# MCXC444 register map
Vendor: NXP Semiconductors; Series: MCX; File version: 1.6
CPU: CM0PLUS r0p0, little endian, no MPU, no FPU, VTOR, 2 interrupt priority bits
Registers are 32-bit, read-write, reset 0x0 unless marked. A register's access mark holds for its fields unless they carry their own. Offsets are from the block's base; [hi:lo] are bit positions; {n}, {i} and the like mark numbered series.

## FTFA_FlashConfig — Flash configuration field
Base 0x00000400; register names take the prefix NV_
0x00 BACKKEY3 8-bit ro reset 0xFF — Backdoor Comparison Key 3.
  [7:0] KEY — Backdoor Comparison Key.
0x01 BACKKEY2 8-bit ro reset 0xFF — Backdoor Comparison Key 2.
  [7:0] KEY — Backdoor Comparison Key.
0x02 BACKKEY1 8-bit ro reset 0xFF — Backdoor Comparison Key 1.
  [7:0] KEY — Backdoor Comparison Key.
0x03 BACKKEY0 8-bit ro reset 0xFF — Backdoor Comparison Key 0.
  [7:0] KEY — Backdoor Comparison Key.
0x04 BACKKEY7 8-bit ro reset 0xFF — Backdoor Comparison Key 7.
  [7:0] KEY — Backdoor Comparison Key.
0x05 BACKKEY6 8-bit ro reset 0xFF — Backdoor Comparison Key 6.
  [7:0] KEY — Backdoor Comparison Key.
0x06 BACKKEY5 8-bit ro reset 0xFF — Backdoor Comparison Key 5.
  [7:0] KEY — Backdoor Comparison Key.
0x07 BACKKEY4 8-bit ro reset 0xFF — Backdoor Comparison Key 4.
  [7:0] KEY — Backdoor Comparison Key.
0x08 FPROT3 8-bit ro reset 0xFF — Non-volatile P-Flash Protection 1 - Low Register
  [7:0] PROT — P-Flash Region Protect
0x09 FPROT2 8-bit ro reset 0xFF — Non-volatile P-Flash Protection 1 - High Register
  [7:0] PROT — P-Flash Region Protect
0x0A FPROT1 8-bit ro reset 0xFF — Non-volatile P-Flash Protection 0 - Low Register
  [7:0] PROT — P-Flash Region Protect
0x0B FPROT0 8-bit ro reset 0xFF — Non-volatile P-Flash Protection 0 - High Register
  [7:0] PROT — P-Flash Region Protect
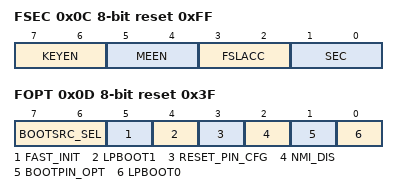
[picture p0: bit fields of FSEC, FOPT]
0x0C FSEC 8-bit ro reset 0xFF — Non-volatile Flash Security Register
  [7:6] KEYEN — Backdoor Key Security Enable
    2=b10 (Backdoor key access enabled); 3=b11 (Backdoor key access disabled)
  [5:4] MEEN
    2=b10 (Mass erase is disabled); 3=b11 (Mass erase is enabled)
  [3:2] FSLACC — Freescale Failure Analysis Access Code
    2=b10 (Freescale factory access denied); 3=b11 (Freescale factory access granted)
  [1:0] SEC — Flash Security
    2=b10 (MCU security status is unsecure); 3=b11 (MCU security status is secure)
0x0D FOPT 8-bit ro reset 0x3F — Non-volatile Flash Option Register
  [7:6] BOOTSRC_SEL — Boot source selection
    0=b00 (Boot from Flash); 2=b10 (Boot from ROM); 3=b11 (Boot from ROM)
  [5] FAST_INIT
    0=b0 (Slower initialization); 1=b1 (Fast Initialization)
  [4] LPBOOT1
    0=b0 (Core and system clock divider (OUTDIV1) is 0x7 (divide by 8) when LPBOOT0=0 or 0x3 (divide by 4) when LPBOOT0=1.); 1=b1 (Core and system clock divider (OUTDIV1) is 0x1 (divide by 2) when LPBOOT0=0 or 0x0 (divide by 1) when LPBOOT0=1.)
  [3] RESET_PIN_CFG
    0=b0 (RESET pin is disabled following a POR and cannot be enabled as reset function); 1=b1 (RESET_b pin is dedicated)
  [2] NMI_DIS
    0=b0 (NMI interrupts are always blocked); 1=b1 (NMI_b pin/interrupts reset default to enabled)
  [1] BOOTPIN_OPT
    0=b0 (Force Boot from ROM if BOOTCFG0 asserted, where BOOTCFG0 is the boot config function which is muxed with NMI pin); 1=b1 (Boot source configured by FOPT (BOOTSRC_SEL) bits)
  [0] LPBOOT0
    0=b0 (Core and system clock divider (OUTDIV1) is 0x7 (divide by 8) when LPBOOT1=0 or 0x1 (divide by 2) when LPBOOT1=1.); 1=b1 (Core and system clock divider (OUTDIV1) is 0x3 (divide by 4) when LPBOOT1=0 or 0x0 (divide by 1) when LPBOOT1=1.)

## FTFA — Flash Memory Interface
Base 0x40020000; register names take the prefix FTFA_
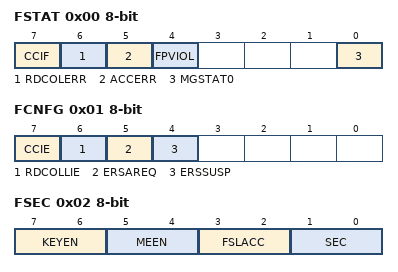
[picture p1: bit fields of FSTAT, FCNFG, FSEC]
0x00 FSTAT 8-bit — Flash Status Register
  [7] CCIF — Command Complete Interrupt Flag
    0=b0 (Flash command in progress); 1=b1 (Flash command has completed)
  [6] RDCOLERR — Flash Read Collision Error Flag
    0=b0 (No collision error detected); 1=b1 (Collision error detected)
  [5] ACCERR — Flash Access Error Flag
    0=b0 (No access error detected); 1=b1 (Access error detected)
  [4] FPVIOL — Flash Protection Violation Flag
    0=b0 (No protection violation detected); 1=b1 (Protection violation detected)
  [0] MGSTAT0 ro — Memory Controller Command Completion Status Flag
0x01 FCNFG 8-bit — Flash Configuration Register
  [7] CCIE — Command Complete Interrupt Enable
    0=b0 (Command complete interrupt disabled); 1=b1 (Command complete interrupt enabled. An interrupt request is generated whenever the FSTAT[CCIF] flag is set.)
  [6] RDCOLLIE — Read Collision Error Interrupt Enable
    0=b0 (Read collision error interrupt disabled); 1=b1 (Read collision error interrupt enabled. An interrupt request is generated whenever a flash memory read collision error is detected (see the description of FSTAT[RDCOLERR]).)
  [5] ERSAREQ ro — Erase All Request
    0=b0 (No request or request complete); 1=b1 (Request to: run the Erase All Blocks command, verify the erased state, program the security byte in the Flash Configuration Field to the unsecure state, and release MCU security by setting the FSEC[SEC] field to the unsecure state.)
  [4] ERSSUSP — Erase Suspend
    0=b0 (No suspend requested); 1=b1 (Suspend the current Erase Flash Sector command execution.)
0x02 FSEC 8-bit ro reset not defined — Flash Security Register
  [7:6] KEYEN — Backdoor Key Security Enable
    0=b00 (Backdoor key access disabled); 1=b01 (Backdoor key access disabled (preferred KEYEN state to disable backdoor key access)); 2=b10 (Backdoor key access enabled); 3=b11 (Backdoor key access disabled)
  [5:4] MEEN — Mass Erase Enable Bits
    0=b00 (Mass erase is enabled); 1=b01 (Mass erase is enabled); 2=b10 (Mass erase is disabled); 3=b11 (Mass erase is enabled)
  [3:2] FSLACC — Freescale Failure Analysis Access Code
    0=b00 (Freescale factory access granted); 1=b01 (Freescale factory access denied); 2=b10 (Freescale factory access denied); 3=b11 (Freescale factory access granted)
  [1:0] SEC — Flash Security
    0=b00 (MCU security status is secure.); 1=b01 (MCU security status is secure.); 2=b10 (MCU security status is unsecure. (The standard shipping condition of the flash memory module is unsecure.)); 3=b11 (MCU security status is secure.)
0x03 FOPT 8-bit ro reset not defined — Flash Option Register
  [7:0] OPT — Nonvolatile Option
0x04 FCCOB{x} (x=3,2,1,0,7,6,5,4,B,A,9,8; step 0x1) 8-bit — Flash Common Command Object Registers
  [7:0] CCOBn — The FCCOB register provides a command code and relevant parameters to the memory controller
0x10 FPROT{x} (x=3,2,1,0; step 0x1) 8-bit reset not defined — Program Flash Protection Registers
  [7:0] PROT — Program Flash Region Protect
    0=b00000000 (Program flash region is protected.); 1=b00000001 (Program flash region is not protected)
